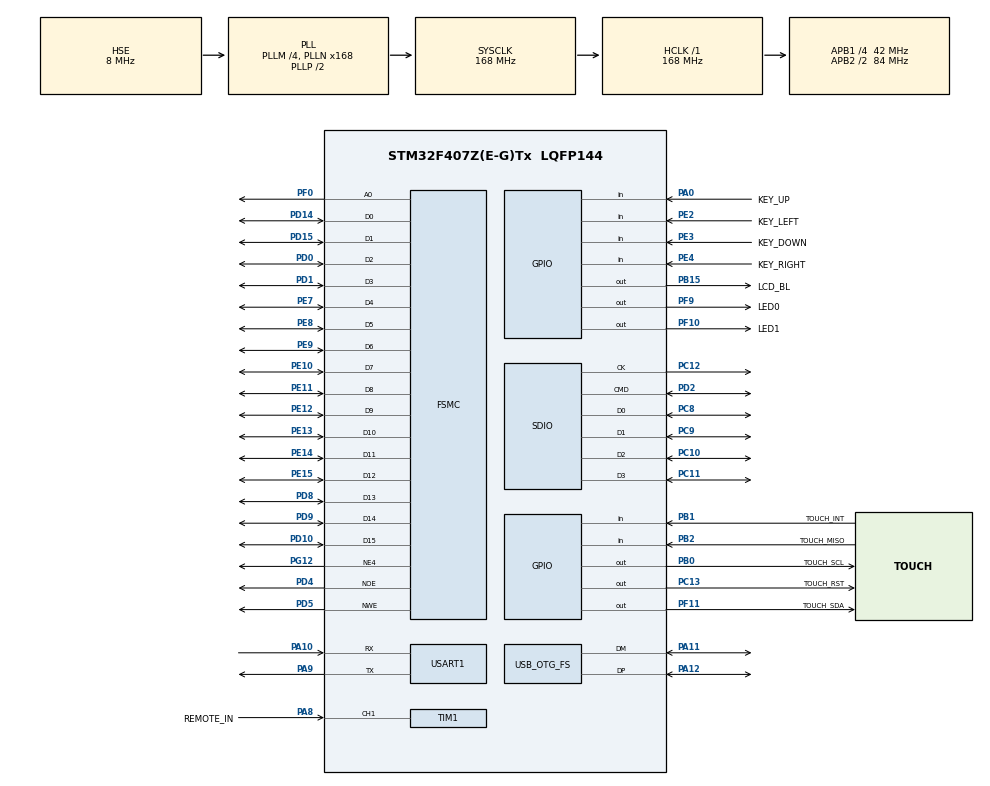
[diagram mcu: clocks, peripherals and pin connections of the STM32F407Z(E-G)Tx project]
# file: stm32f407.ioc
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Dma.Request0=USART1_RX
Dma.Request1=USART1_TX
Dma.USART1_RX.0.Direction=DMA_PERIPH_TO_MEMORY
Dma.USART1_RX.0.FIFOMode=DMA_FIFOMODE_DISABLE
Dma.USART1_RX.0.Instance=DMA2_Stream2
Dma.USART1_RX.0.MemDataAlignment=DMA_MDATAALIGN_BYTE
Dma.USART1_RX.0.MemInc=DMA_MINC_ENABLE
Dma.USART1_RX.0.Mode=DMA_NORMAL
Dma.USART1_RX.0.PeriphDataAlignment=DMA_PDATAALIGN_BYTE
Dma.USART1_RX.0.PeriphInc=DMA_PINC_DISABLE
Dma.USART1_RX.0.Priority=DMA_PRIORITY_LOW
Dma.USART1_TX.1.Direction=DMA_MEMORY_TO_PERIPH
Dma.USART1_TX.1.FIFOMode=DMA_FIFOMODE_DISABLE
Dma.USART1_TX.1.Instance=DMA2_Stream7
Dma.USART1_TX.1.MemDataAlignment=DMA_MDATAALIGN_BYTE
Dma.USART1_TX.1.MemInc=DMA_MINC_ENABLE
Dma.USART1_TX.1.Mode=DMA_NORMAL
Dma.USART1_TX.1.PeriphDataAlignment=DMA_PDATAALIGN_BYTE
Dma.USART1_TX.1.PeriphInc=DMA_PINC_DISABLE
Dma.USART1_TX.1.Priority=DMA_PRIORITY_LOW
FREERTOS.Queues01=Queue_Button,16,button_send_data_t,0,Dynamic,NULL,NULL
FREERTOS.Tasks01=defaultTask,24,128,StartDefaultTask,Default,NULL,Dynamic,NULL,NULL;Task_Main,24,512,Start_Task_Main,As external,NULL,Dynamic,NULL,NULL;Task_TimerIRQ,24,512,Start_Task_TimerIRQ,As external,NULL,Dynamic,NULL,NULL
FSMC.ExtendedMode1=FSMC_EXTENDED_MODE_ENABLE
FSMC.WriteOperation1=FSMC_WRITE_OPERATION_ENABLE
Mcu.Family=STM32F4
Mcu.Name=STM32F407Z(E-G)Tx
Mcu.Package=LQFP144
NVIC.DMA2_Stream2_IRQn=true\:5\:0\:false\:false\:true\:true\:false\:true\:true
NVIC.DMA2_Stream7_IRQn=true\:5\:0\:false\:false\:true\:true\:false\:true\:true
NVIC.OTG_FS_IRQn=true\:5\:0\:false\:false\:true\:true\:false\:true\:true
NVIC.PriorityGroup=NVIC_PRIORITYGROUP_4
NVIC.TIM1_CC_IRQn=true\:5\:0\:false\:false\:true\:true\:true\:true\:true
NVIC.TIM1_UP_TIM10_IRQn=true\:5\:0\:false\:false\:true\:true\:true\:true\:true
NVIC.TIM6_DAC_IRQn=true\:15\:0\:false\:false\:true\:false\:false\:true\:true
NVIC.TIM7_IRQn=true\:5\:0\:false\:false\:true\:true\:true\:true\:true
NVIC.TimeBase=TIM6_DAC_IRQn
NVIC.TimeBaseIP=TIM6
NVIC.USART1_IRQn=true\:5\:0\:false\:false\:true\:true\:true\:true\:true
PA0-WKUP.GPIO_Label=KEY_UP
PA0-WKUP.GPIO_PuPd=GPIO_PULLDOWN
PA0-WKUP.Signal=GPIO_Input
PA10.Mode=Asynchronous
PA10.Signal=USART1_RX
PA11.Mode=Device_Only
PA11.Signal=USB_OTG_FS_DM
PA12.Mode=Device_Only
PA12.Signal=USB_OTG_FS_DP
PA13.Mode=Serial_Wire
PA13.Signal=SYS_JTMS-SWDIO
PA14.Mode=Serial_Wire
PA14.Signal=SYS_JTCK-SWCLK
PA8.GPIO_Label=REMOTE_IN
PA8.GPIO_PuPd=GPIO_PULLUP
PA8.GPIO_Speed=GPIO_SPEED_FREQ_HIGH
PA8.Signal=S_TIM1_CH1
PA9.Mode=Asynchronous
PA9.Signal=USART1_TX
PB0.GPIO_Label=TOUCH_SCL 
PB0.GPIO_ModeDefaultOutputPP=GPIO_MODE_OUTPUT_OD
PB0.GPIO_PuPd=GPIO_PULLUP
PB0.PinState=GPIO_PIN_SET
PB0.Signal=GPIO_Output
PB1.GPIO_Label=TOUCH_INT 
PB1.GPIO_PuPd=GPIO_PULLUP
PB1.Signal=GPIO_Input
PB15.GPIO_Label=LCD_BL
PB15.PinState=GPIO_PIN_SET
PB15.Signal=GPIO_Output
PB2.GPIO_Label=TOUCH_MISO
PB2.GPIO_PuPd=GPIO_PULLUP
PB2.Signal=GPIO_Input
PC10.Mode=SD_4_bits_Wide_bus
PC10.Signal=SDIO_D2
PC11.Mode=SD_4_bits_Wide_bus
PC11.Signal=SDIO_D3
PC12.Mode=SD_4_bits_Wide_bus
PC12.Signal=SDIO_CK
PC13-ANTI_TAMP.GPIO_Label=TOUCH_RST 
PC13-ANTI_TAMP.GPIO_PuPd=GPIO_PULLUP
PC13-ANTI_TAMP.PinState=GPIO_PIN_SET
PC13-ANTI_TAMP.Signal=GPIO_Output
PC14-OSC32_IN.Mode=LSE-External-Oscillator
PC14-OSC32_IN.Signal=RCC_OSC32_IN
PC15-OSC32_OUT.Mode=LSE-External-Oscillator
PC15-OSC32_OUT.Signal=RCC_OSC32_OUT
PC8.Mode=SD_4_bits_Wide_bus
PC8.Signal=SDIO_D0
PC9.Mode=SD_4_bits_Wide_bus
PC9.Signal=SDIO_D1
PD0.Signal=FSMC_D2_DA2
PD1.Signal=FSMC_D3_DA3
PD10.Signal=FSMC_D15_DA15
PD14.Signal=FSMC_D0_DA0
PD15.Signal=FSMC_D1_DA1
PD2.Mode=SD_4_bits_Wide_bus
PD2.Signal=SDIO_CMD
PD4.Signal=FSMC_NOE
PD5.Signal=FSMC_NWE
PD8.Signal=FSMC_D13_DA13
PD9.Signal=FSMC_D14_DA14
PE10.Signal=FSMC_D7_DA7
PE11.Signal=FSMC_D8_DA8
PE12.Signal=FSMC_D9_DA9
PE13.Signal=FSMC_D10_DA10
PE14.Signal=FSMC_D11_DA11
PE15.Signal=FSMC_D12_DA12
PE2.GPIO_Label=KEY_LEFT
PE2.GPIO_PuPd=GPIO_PULLUP
PE2.Signal=GPIO_Input
PE3.GPIO_Label=KEY_DOWN
PE3.GPIO_PuPd=GPIO_PULLUP
PE3.Signal=GPIO_Input
PE4.GPIO_Label=KEY_RIGHT
PE4.GPIO_PuPd=GPIO_PULLUP
PE4.Signal=GPIO_Input
PE7.Signal=FSMC_D4_DA4
PE8.Signal=FSMC_D5_DA5
PE9.Signal=FSMC_D6_DA6
PF0.Signal=FSMC_A0
PF10.GPIO_Label=LED1
PF10.PinState=GPIO_PIN_SET
PF10.Signal=GPIO_Output
PF11.GPIO_Label=TOUCH_SDA 
PF11.GPIO_ModeDefaultOutputPP=GPIO_MODE_OUTPUT_OD
PF11.GPIO_PuPd=GPIO_PULLUP
PF11.PinState=GPIO_PIN_SET
PF11.Signal=GPIO_Output
PF12.Signal=FSMC_A6
PF9.GPIO_Label=LED0
PF9.PinState=GPIO_PIN_SET
PF9.Signal=GPIO_Output
PG12.Mode=NorPsramChipSelect4_1
PG12.Signal=FSMC_NE4
PH0-OSC_IN.Mode=HSE-External-Oscillator
PH0-OSC_IN.Signal=RCC_OSC_IN
PH1-OSC_OUT.Mode=HSE-External-Oscillator
PH1-OSC_OUT.Signal=RCC_OSC_OUT
ProjectManager.HeapSize=0x200
ProjectManager.StackSize=0x400
ProjectManager.TargetToolchain=STM32CubeIDE
RCC.48MHZClocksFreq_Value=48000000
RCC.AHBFreq_Value=168000000
RCC.APB1CLKDivider=RCC_HCLK_DIV4
RCC.APB1Freq_Value=42000000
RCC.APB1TimFreq_Value=84000000
RCC.APB2CLKDivider=RCC_HCLK_DIV2
RCC.APB2Freq_Value=84000000
RCC.APB2TimFreq_Value=168000000
RCC.CortexFreq_Value=168000000
RCC.HCLKFreq_Value=168000000
RCC.HSE_VALUE=8000000
RCC.HSI_VALUE=16000000
RCC.PLLM=4
RCC.PLLN=168
RCC.PLLQ=7
RCC.RCC_RTC_Clock_Source=RCC_RTCCLKSOURCE_LSE
RCC.RCC_RTC_Clock_SourceVirtual=RCC_RTCCLKSOURCE_LSE
RCC.SYSCLKFreq_VALUE=168000000
RCC.SYSCLKSource=RCC_SYSCLKSOURCE_PLLCLK
RCC.VCOOutputFreq_Value=336000000
RTC.Date=15
RTC.Month=RTC_MONTH_OCTOBER
RTC.WeekDay=RTC_WEEKDAY_WEDNESDAY
RTC.Year=25
SDIO.ClockDiv=1
SH.FSMC_A0.0=FSMC_A0,1b-a1
SH.FSMC_A6.0=FSMC_A6
SH.FSMC_D0_DA0.0=FSMC_D0,16b-d1
SH.FSMC_D10_DA10.0=FSMC_D10,16b-d1
SH.FSMC_D11_DA11.0=FSMC_D11,16b-d1
SH.FSMC_D12_DA12.0=FSMC_D12,16b-d1
SH.FSMC_D13_DA13.0=FSMC_D13,16b-d1
SH.FSMC_D14_DA14.0=FSMC_D14,16b-d1
SH.FSMC_D15_DA15.0=FSMC_D15,16b-d1
SH.FSMC_D1_DA1.0=FSMC_D1,16b-d1
SH.FSMC_D2_DA2.0=FSMC_D2,16b-d1
SH.FSMC_D3_DA3.0=FSMC_D3,16b-d1
SH.FSMC_D4_DA4.0=FSMC_D4,16b-d1
SH.FSMC_D5_DA5.0=FSMC_D5,16b-d1
SH.FSMC_D6_DA6.0=FSMC_D6,16b-d1
SH.FSMC_D7_DA7.0=FSMC_D7,16b-d1
SH.FSMC_D8_DA8.0=FSMC_D8,16b-d1
SH.FSMC_D9_DA9.0=FSMC_D9,16b-d1
SH.FSMC_NOE.0=FSMC_NOE,Sram1
SH.FSMC_NWE.0=FSMC_NWE,Sram1
SH.S_TIM1_CH1.0=TIM1_CH1,Input_Capture1_from_TI1
TIM1.Channel-Input_Capture1_from_TI1=TIM_CHANNEL_1
TIM1.ICFilter_CH1=3
TIM1.Period=10000
TIM1.Prescaler=168-1
TIM7.Period=84-1
TIM7.Prescaler=1000-1
USART1.VirtualMode=VM_ASYNC
USB_DEVICE.CLASS_NAME_FS=CDC
USB_DEVICE.VirtualMode-CDC_FS=Cdc
USB_DEVICE.VirtualModeFS=Cdc_FS
USB_OTG_FS.VirtualMode=Device_Only
VP_FATFS_VS_SDIO.Mode=SDIO
VP_FREERTOS_VS_CMSIS_V2.Mode=CMSIS_V2
VP_RTC_VS_RTC_Activate.Mode=RTC_Enabled
VP_RTC_VS_RTC_Calendar.Mode=RTC_Calendar
VP_SYS_VS_tim6.Mode=TIM6
VP_TIM1_VS_ClockSourceINT.Mode=Internal
VP_TIM7_VS_ClockSourceINT.Mode=Enable_Timer
VP_USB_DEVICE_VS_USB_DEVICE_CDC_FS.Mode=CDC_FS
board=custom

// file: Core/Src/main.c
/* USER CODE BEGIN Header */
/**
  ******************************************************************************
  * @file           : main.c
  * @brief          : Main program body
  ******************************************************************************
  * @attention
  *
  * Copyright (c) 2025 STMicroelectronics.
  * All rights reserved.
  *
  * This software is licensed under terms that can be found in the LICENSE file
  * in the root directory of this software component.
  * If no LICENSE file comes with this software, it is provided AS-IS.
  *
  ******************************************************************************
  */
/* USER CODE END Header */
#include "main.h"
#include "cmsis_os.h"
#include "dma.h"
#include "fatfs.h"
#include "rtc.h"
#include "sdio.h"
#include "tim.h"
#include "usart.h"
#include "usb_device.h"
#include "gpio.h"
#include "fsmc.h"

/* USER CODE BEGIN Includes */

#include "main_link.h"
#include "MMInterface/Remote/remote.h"

/* USER CODE END Includes */

/* USER CODE BEGIN PV */

// ????????
volatile uint32_t systemTimeMs = 0;

/* USER CODE END PV */

void SystemClock_Config(void);
void MX_FREERTOS_Init(void);

int main(void)
{

  /* MCU Configuration--------------------------------------------------------*/

  /* Reset of all peripherals, Initializes the Flash interface and the Systick. */
  HAL_Init();

  /* Configure the system clock */
  SystemClock_Config();

  /* Initialize all configured peripherals */
  MX_GPIO_Init();
  MX_DMA_Init();
  MX_USART1_UART_Init();
  MX_TIM7_Init();
  MX_RTC_Init();
  MX_FSMC_Init();
  MX_SDIO_SD_Init();
  MX_FATFS_Init();
  MX_TIM1_Init();
  /* USER CODE BEGIN 2 */

    Main_Setup();

  /* USER CODE END 2 */

  /* Init scheduler */
  osKernelInitialize();  /* Call init function for freertos objects (in cmsis_os2.c) */
  MX_FREERTOS_Init();

  /* Start scheduler */
  osKernelStart();

  /* We should never get here as control is now taken by the scheduler */

  /* Infinite loop */
    while (1)
    {

    }
}

void SystemClock_Config(void)
{
  RCC_OscInitTypeDef RCC_OscInitStruct = {0};
  RCC_ClkInitTypeDef RCC_ClkInitStruct = {0};

  /** Configure the main internal regulator output voltage
  */
  __HAL_RCC_PWR_CLK_ENABLE();
  __HAL_PWR_VOLTAGESCALING_CONFIG(PWR_REGULATOR_VOLTAGE_SCALE1);

  /** Initializes the RCC Oscillators according to the specified parameters
  * in the RCC_OscInitTypeDef structure.
  */
  RCC_OscInitStruct.OscillatorType = RCC_OSCILLATORTYPE_HSE|RCC_OSCILLATORTYPE_LSE;
  RCC_OscInitStruct.HSEState = RCC_HSE_ON;
  RCC_OscInitStruct.LSEState = RCC_LSE_ON;
  RCC_OscInitStruct.PLL.PLLState = RCC_PLL_ON;
  RCC_OscInitStruct.PLL.PLLSource = RCC_PLLSOURCE_HSE;
  RCC_OscInitStruct.PLL.PLLM = 4;
  RCC_OscInitStruct.PLL.PLLN = 168;
  RCC_OscInitStruct.PLL.PLLP = RCC_PLLP_DIV2;
  RCC_OscInitStruct.PLL.PLLQ = 7;
  if (HAL_RCC_OscConfig(&RCC_OscInitStruct) != HAL_OK)
  {
    Error_Handler();
  }

  /** Initializes the CPU, AHB and APB buses clocks
  */
  RCC_ClkInitStruct.ClockType = RCC_CLOCKTYPE_HCLK|RCC_CLOCKTYPE_SYSCLK
                              |RCC_CLOCKTYPE_PCLK1|RCC_CLOCKTYPE_PCLK2;
  RCC_ClkInitStruct.SYSCLKSource = RCC_SYSCLKSOURCE_PLLCLK;
  RCC_ClkInitStruct.AHBCLKDivider = RCC_SYSCLK_DIV1;
  RCC_ClkInitStruct.APB1CLKDivider = RCC_HCLK_DIV4;
  RCC_ClkInitStruct.APB2CLKDivider = RCC_HCLK_DIV2;

  if (HAL_RCC_ClockConfig(&RCC_ClkInitStruct, FLASH_LATENCY_5) != HAL_OK)
  {
    Error_Handler();
  }
}

/* USER CODE BEGIN 4 */

uint32_t getSystemTimeMs()
{
    return systemTimeMs;
}

void HAL_TIM_IC_CaptureCallback(TIM_HandleTypeDef *htim)
{
    Remote_OnInputCapture(htim);
}

/* USER CODE END 4 */

void HAL_TIM_PeriodElapsedCallback(TIM_HandleTypeDef *htim)
{
  if (htim->Instance == TIM6)
  {
    HAL_IncTick();
  }
  /* USER CODE BEGIN Callback 1 */
    if (htim->Instance == TIM6)
        systemTimeMs++;
    Remote_OnTimerPeriodElapsed(htim);
  /* USER CODE END Callback 1 */
}

void Error_Handler(void)
{
    __disable_irq();
    while (1)
    {
    }
}

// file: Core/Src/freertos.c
/* USER CODE BEGIN Header */
/**
  ******************************************************************************
  * File Name          : freertos.c
  * Description        : Code for freertos applications
  ******************************************************************************
  * @attention
  *
  * Copyright (c) 2025 STMicroelectronics.
  * All rights reserved.
  *
  * This software is licensed under terms that can be found in the LICENSE file
  * in the root directory of this software component.
  * If no LICENSE file comes with this software, it is provided AS-IS.
  *
  ******************************************************************************
  */
/* USER CODE END Header */

#include "FreeRTOS.h"
#include "task.h"
#include "main.h"
#include "cmsis_os.h"

/* USER CODE BEGIN Includes */

#include "MMInterface/Button/Button_Controller.h"

/* USER CODE END Includes */

/* Definitions for defaultTask */
osThreadId_t defaultTaskHandle;
const osThreadAttr_t defaultTask_attributes = {
  .name = "defaultTask",
  .stack_size = 128 * 4,
  .priority = (osPriority_t) osPriorityNormal,
};
/* Definitions for Task_Main */
osThreadId_t Task_MainHandle;
const osThreadAttr_t Task_Main_attributes = {
  .name = "Task_Main",
  .stack_size = 512 * 4,
  .priority = (osPriority_t) osPriorityNormal,
};
/* Definitions for Task_TimerIRQ */
osThreadId_t Task_TimerIRQHandle;
const osThreadAttr_t Task_TimerIRQ_attributes = {
  .name = "Task_TimerIRQ",
  .stack_size = 512 * 4,
  .priority = (osPriority_t) osPriorityNormal,
};
/* Definitions for Queue_Button */
osMessageQueueId_t Queue_ButtonHandle;
const osMessageQueueAttr_t Queue_Button_attributes = {
  .name = "Queue_Button"
};

void StartDefaultTask(void *argument);
extern void Start_Task_Main(void *argument);
extern void Start_Task_TimerIRQ(void *argument);

extern void MX_USB_DEVICE_Init(void);
void MX_FREERTOS_Init(void); /* (MISRA C 2004 rule 8.1) */

void MX_FREERTOS_Init(void) {

  /* Create the queue(s) */
  /* creation of Queue_Button */
  Queue_ButtonHandle = osMessageQueueNew (16, sizeof(button_send_data_t), &Queue_Button_attributes);

  /* Create the thread(s) */
  /* creation of defaultTask */
  defaultTaskHandle = osThreadNew(StartDefaultTask, NULL, &defaultTask_attributes);

  /* creation of Task_Main */
  Task_MainHandle = osThreadNew(Start_Task_Main, NULL, &Task_Main_attributes);

  /* creation of Task_TimerIRQ */
  Task_TimerIRQHandle = osThreadNew(Start_Task_TimerIRQ, NULL, &Task_TimerIRQ_attributes);

}

void StartDefaultTask(void *argument)
{
  /* init code for USB_DEVICE */
  MX_USB_DEVICE_Init();
    for (;;)
    {
        osDelay(1);
    }
}
